# SA3_SS_SA_UL_0_SA_UL_PKA_EIP29T2_40920000h register map
Vendor: Texas Instruments
Peripheral module from a debugger description file (folder AM275x).
Registers are 32-bit, read-write, reset 0x0 unless marked. A register's access mark holds for its fields unless they carry their own. Offsets are as the file gives them; lines under a group give offsets from that group; [hi:lo] are bit positions; {n}, {i} and the like mark numbered series; 'fields as' and 'values as' point back to an identical list; <NAME> marks a mode.

## sa_ul_pka_eip29t2
0x00 SA_UL_PKA_EIP29T2_PKA_APTR — Please refer to eip29t2 HW Reference Manual for details
  [10:0] APTR
0x04 SA_UL_PKA_EIP29T2_PKA_BPTR — Please refer to eip29t2 HW Reference Manual for details
  [10:0] BPTR
0x08 SA_UL_PKA_EIP29T2_PKA_CPTR — Please refer to eip29t2 HW Reference Manual for details
  [10:0] CPTR
0x0C SA_UL_PKA_EIP29T2_PKA_DPTR — Please refer to eip29t2 HW Reference Manual for details
  [10:0] DPTR
0x10 SA_UL_PKA_EIP29T2_PKA_ALENGTH — Please refer to eip29t2 HW Reference Manual for details
  [8:0] ALENGTH
0x14 SA_UL_PKA_EIP29T2_PKA_BLENGTH — Please refer to eip29t2 HW Reference Manual for details
  [8:0] BLENGTH
0x18 SA_UL_PKA_EIP29T2_PKA_SHIFT — Please refer to eip29t2 HW Reference Manual for details
  [4:0] BITS_TO_SHIFT
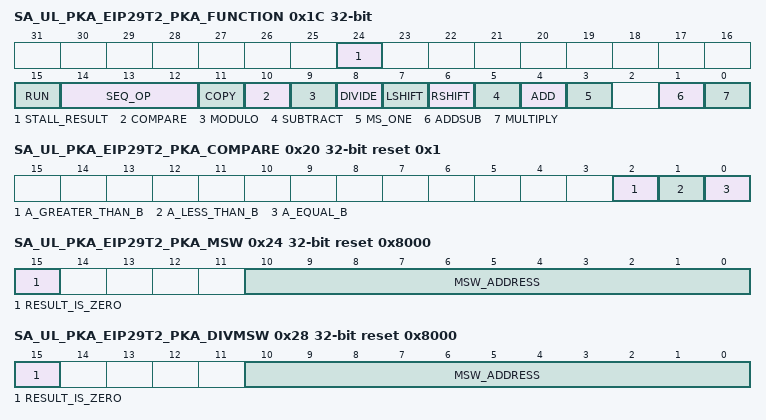
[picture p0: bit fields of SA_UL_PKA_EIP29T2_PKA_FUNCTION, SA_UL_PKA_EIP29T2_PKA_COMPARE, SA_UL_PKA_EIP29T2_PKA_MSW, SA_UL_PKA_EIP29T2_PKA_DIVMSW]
0x1C SA_UL_PKA_EIP29T2_PKA_FUNCTION access per field — Please refer to eip29t2 HW Reference Manual for details
  [24] STALL_RESULT rw — Please refer to eip29t2 HW Reference Manual for details
  [15] RUN wo — Please refer to eip29t2 HW Reference Manual for details
  [14:12] SEQ_OP rw — Please refer to eip29t2 HW Reference Manual for details
  [11] COPY rw — Please refer to eip29t2 HW Reference Manual for details
  [10] COMPARE rw — Please refer to eip29t2 HW Reference Manual for details
  [9] MODULO rw — Please refer to eip29t2 HW Reference Manual for details
  [8] DIVIDE rw — Please refer to eip29t2 HW Reference Manual for details
  [7] LSHIFT rw — Please refer to eip29t2 HW Reference Manual for details
  [6] RSHIFT rw — Please refer to eip29t2 HW Reference Manual for details
  [5] SUBTRACT rw — Please refer to eip29t2 HW Reference Manual for details
  [4] ADD rw — Please refer to eip29t2 HW Reference Manual for details
  [3] MS_ONE rw — Please refer to eip29t2 HW Reference Manual for details
  [1] ADDSUB rw — Please refer to eip29t2 HW Reference Manual for details
  [0] MULTIPLY rw — Please refer to eip29t2 HW Reference Manual for details
0x20 SA_UL_PKA_EIP29T2_PKA_COMPARE ro reset 0x1 — Please refer to eip29t2 HW Reference Manual for details
  [2] A_GREATER_THAN_B — Please refer to eip29t2 HW Reference Manual for details
  [1] A_LESS_THAN_B — Please refer to eip29t2 HW Reference Manual for details
  [0] A_EQUAL_B — Please refer to eip29t2 HW Reference Manual for details
0x24 SA_UL_PKA_EIP29T2_PKA_MSW ro reset 0x8000 — Please refer to eip29t2 HW Reference Manual for details
  [15] RESULT_IS_ZERO — Please refer to eip29t2 HW Reference Manual for details
  [10:0] MSW_ADDRESS — Please refer to eip29t2 HW Reference Manual for details
0x28 SA_UL_PKA_EIP29T2_PKA_DIVMSW ro reset 0x8000 — Please refer to eip29t2 HW Reference Manual for details
  fields as SA_UL_PKA_EIP29T2_PKA_MSW
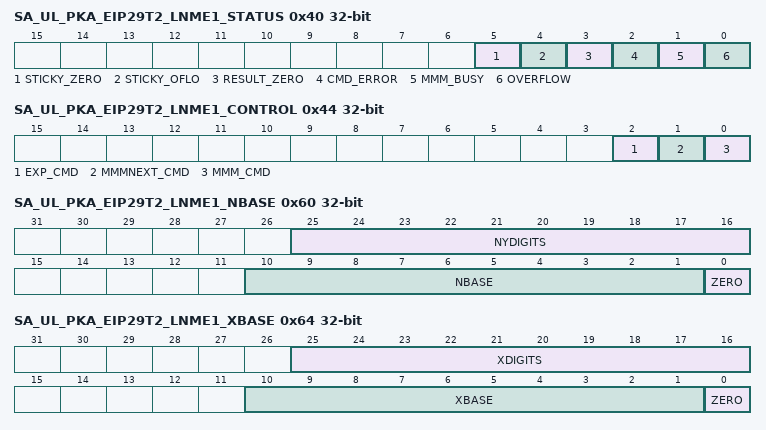
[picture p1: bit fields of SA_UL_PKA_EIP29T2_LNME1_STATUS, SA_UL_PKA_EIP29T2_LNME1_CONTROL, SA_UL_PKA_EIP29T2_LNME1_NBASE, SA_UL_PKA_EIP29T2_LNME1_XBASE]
0x40 SA_UL_PKA_EIP29T2_LNME1_STATUS — Please refer to eip29t2 HW Reference Manual for details
  [5] STICKY_ZERO — Please refer to eip29t2 HW Reference Manual for details
  [4] STICKY_OFLO — Please refer to eip29t2 HW Reference Manual for details
  [3] RESULT_ZERO — Please refer to eip29t2 HW Reference Manual for details
  [2] CMD_ERROR — Please refer to eip29t2 HW Reference Manual for details
  [1] MMM_BUSY — Please refer to eip29t2 HW Reference Manual for details
  [0] OVERFLOW — Please refer to eip29t2 HW Reference Manual for details
0x44 SA_UL_PKA_EIP29T2_LNME1_CONTROL — Please refer to eip29t2 HW Reference Manual for details
  [2] EXP_CMD — Please refer to eip29t2 HW Reference Manual for details
  [1] MMMNEXT_CMD — Please refer to eip29t2 HW Reference Manual for details
  [0] MMM_CMD — Please refer to eip29t2 HW Reference Manual for details
0x60 SA_UL_PKA_EIP29T2_LNME1_NBASE access per field — Please refer to eip29t2 HW Reference Manual for details
  [25:16] NYDIGITS rw — Please refer to eip29t2 HW Reference Manual for details
  [10:1] NBASE rw — Please refer to eip29t2 HW Reference Manual for details
  [0] ZERO ro — Please refer to eip29t2 HW Reference Manual for details
0x64 SA_UL_PKA_EIP29T2_LNME1_XBASE access per field — Please refer to eip29t2 HW Reference Manual for details
  [25:16] XDIGITS rw — Please refer to eip29t2 HW Reference Manual for details
  [10:1] XBASE rw — Please refer to eip29t2 HW Reference Manual for details
  [0] ZERO ro — Please refer to eip29t2 HW Reference Manual for details
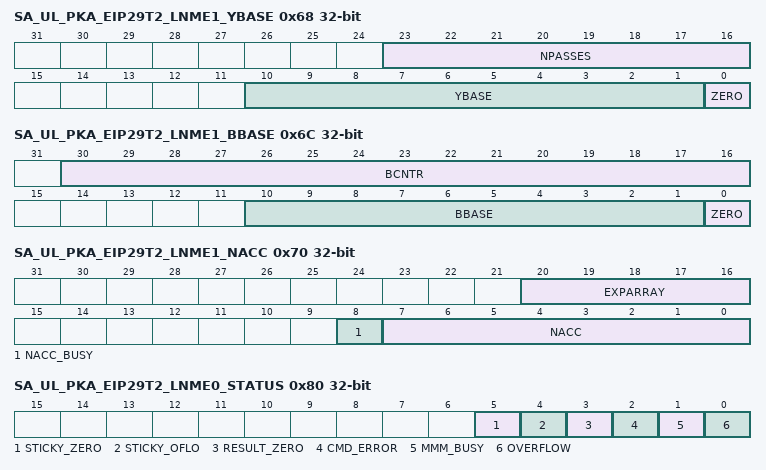
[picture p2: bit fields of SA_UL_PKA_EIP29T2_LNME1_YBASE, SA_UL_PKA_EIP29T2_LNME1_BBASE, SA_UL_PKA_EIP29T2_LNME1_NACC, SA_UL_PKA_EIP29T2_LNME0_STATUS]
0x68 SA_UL_PKA_EIP29T2_LNME1_YBASE access per field — Please refer to eip29t2 HW Reference Manual for details
  [23:16] NPASSES rw — Please refer to eip29t2 HW Reference Manual for details
  [10:1] YBASE rw — Please refer to eip29t2 HW Reference Manual for details
  [0] ZERO ro — Please refer to eip29t2 HW Reference Manual for details
0x6C SA_UL_PKA_EIP29T2_LNME1_BBASE access per field — Please refer to eip29t2 HW Reference Manual for details
  [30:16] BCNTR rw — Please refer to eip29t2 HW Reference Manual for details
  [10:1] BBASE rw — Please refer to eip29t2 HW Reference Manual for details
  [0] ZERO ro — Please refer to eip29t2 HW Reference Manual for details
0x70 SA_UL_PKA_EIP29T2_LNME1_NACC — Please refer to eip29t2 HW Reference Manual for details
  [20:16] EXPARRAY — Please refer to eip29t2 HW Reference Manual for details
  [8] NACC_BUSY — Please refer to eip29t2 HW Reference Manual for details
  [7:0] NACC — Please refer to eip29t2 HW Reference Manual for details
0x74 SA_UL_PKA_EIP29T2_LNME1_NZERO — Please refer to eip29t2 HW Reference Manual for details
  [7:0] NZERO
0x80 SA_UL_PKA_EIP29T2_LNME0_STATUS — Please refer to eip29t2 HW Reference Manual for details
  fields as SA_UL_PKA_EIP29T2_LNME1_STATUS
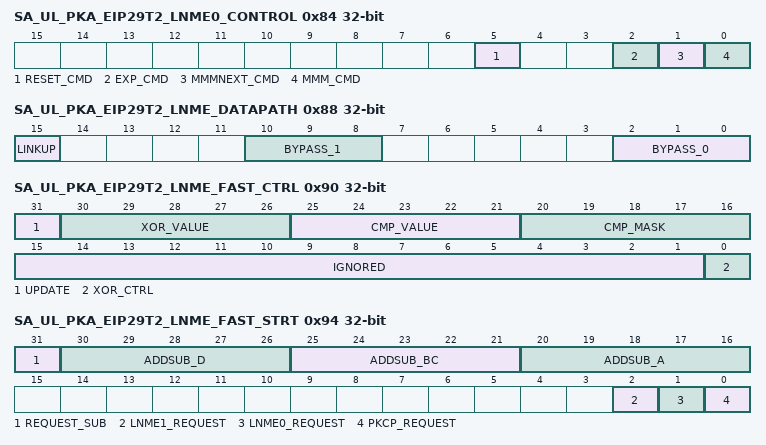
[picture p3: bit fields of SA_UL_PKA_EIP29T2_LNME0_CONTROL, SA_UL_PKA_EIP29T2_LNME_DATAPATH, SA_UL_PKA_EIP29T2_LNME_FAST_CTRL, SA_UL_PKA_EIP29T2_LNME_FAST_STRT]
0x84 SA_UL_PKA_EIP29T2_LNME0_CONTROL — Please refer to eip29t2 HW Reference Manual for details
  [5] RESET_CMD — Please refer to eip29t2 HW Reference Manual for details
  [2] EXP_CMD — Please refer to eip29t2 HW Reference Manual for details
  [1] MMMNEXT_CMD — Please refer to eip29t2 HW Reference Manual for details
  [0] MMM_CMD — Please refer to eip29t2 HW Reference Manual for details
0x88 SA_UL_PKA_EIP29T2_LNME_DATAPATH — Please refer to eip29t2 HW Reference Manual for details
  [15] LINKUP — Please refer to eip29t2 HW Reference Manual for details
  [10:8] BYPASS_1 — Please refer to eip29t2 HW Reference Manual for details
  [2:0] BYPASS_0 — Please refer to eip29t2 HW Reference Manual for details
0x90 SA_UL_PKA_EIP29T2_LNME_FAST_CTRL access per field — Please refer to eip29t2 HW Reference Manual for details
  [31] UPDATE wo — Please refer to eip29t2 HW Reference Manual for details
  [30:26] XOR_VALUE rw — Please refer to eip29t2 HW Reference Manual for details
  [25:21] CMP_VALUE rw — Please refer to eip29t2 HW Reference Manual for details
  [20:16] CMP_MASK rw — Please refer to eip29t2 HW Reference Manual for details
  [15:1] IGNORED ro — Please refer to eip29t2 HW Reference Manual for details
  [0] XOR_CTRL rw — Please refer to eip29t2 HW Reference Manual for details
0x94 SA_UL_PKA_EIP29T2_LNME_FAST_STRT — Please refer to eip29t2 HW Reference Manual for details
  [31] REQUEST_SUB — Please refer to eip29t2 HW Reference Manual for details
  [30:26] ADDSUB_D — Please refer to eip29t2 HW Reference Manual for details
  [25:21] ADDSUB_BC — Please refer to eip29t2 HW Reference Manual for details
  [20:16] ADDSUB_A — Please refer to eip29t2 HW Reference Manual for details
  [2] LNME1_REQUEST — Please refer to eip29t2 HW Reference Manual for details
  [1] LNME0_REQUEST — Please refer to eip29t2 HW Reference Manual for details
  [0] PKCP_REQUEST — Please refer to eip29t2 HW Reference Manual for details
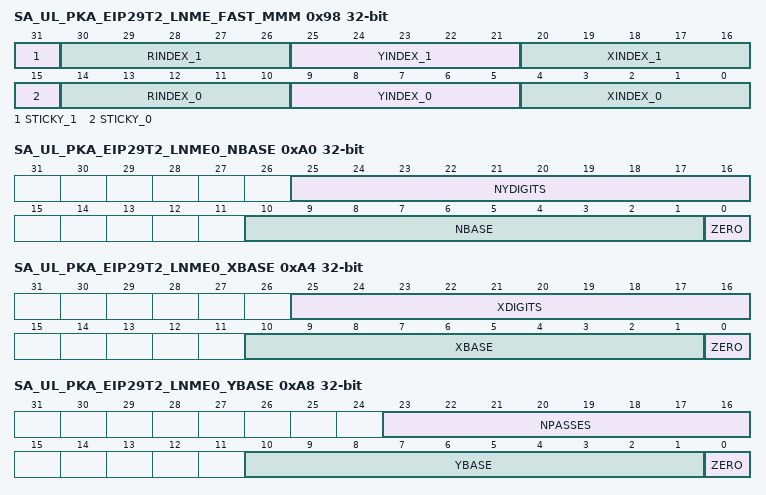
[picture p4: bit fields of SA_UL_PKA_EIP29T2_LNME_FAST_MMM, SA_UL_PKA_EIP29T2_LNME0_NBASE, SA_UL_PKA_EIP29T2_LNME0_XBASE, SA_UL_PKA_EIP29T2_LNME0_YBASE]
0x98 SA_UL_PKA_EIP29T2_LNME_FAST_MMM — Please refer to eip29t2 HW Reference Manual for details
  [31] STICKY_1 — Please refer to eip29t2 HW Reference Manual for details
  [30:26] RINDEX_1 — Please refer to eip29t2 HW Reference Manual for details
  [25:21] YINDEX_1 — Please refer to eip29t2 HW Reference Manual for details
  [20:16] XINDEX_1 — Please refer to eip29t2 HW Reference Manual for details
  [15] STICKY_0 — Please refer to eip29t2 HW Reference Manual for details
  [14:10] RINDEX_0 — Please refer to eip29t2 HW Reference Manual for details
  [9:5] YINDEX_0 — Please refer to eip29t2 HW Reference Manual for details
  [4:0] XINDEX_0 — Please refer to eip29t2 HW Reference Manual for details
0xA0 SA_UL_PKA_EIP29T2_LNME0_NBASE access per field — Please refer to eip29t2 HW Reference Manual for details
  fields as SA_UL_PKA_EIP29T2_LNME1_NBASE
0xA4 SA_UL_PKA_EIP29T2_LNME0_XBASE access per field — Please refer to eip29t2 HW Reference Manual for details
  fields as SA_UL_PKA_EIP29T2_LNME1_XBASE
0xA8 SA_UL_PKA_EIP29T2_LNME0_YBASE access per field — Please refer to eip29t2 HW Reference Manual for details
  fields as SA_UL_PKA_EIP29T2_LNME1_YBASE
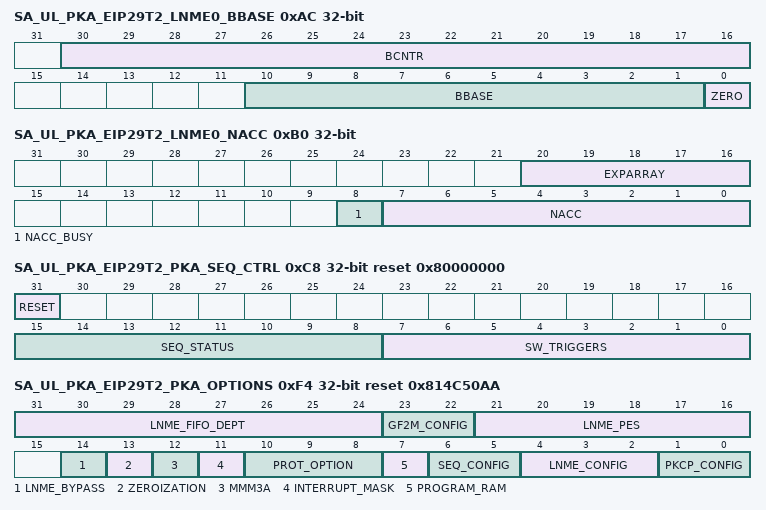
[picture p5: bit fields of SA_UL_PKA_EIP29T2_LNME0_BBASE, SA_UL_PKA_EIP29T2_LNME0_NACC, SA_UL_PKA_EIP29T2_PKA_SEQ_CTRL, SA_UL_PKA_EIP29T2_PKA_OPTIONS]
0xAC SA_UL_PKA_EIP29T2_LNME0_BBASE access per field — Please refer to eip29t2 HW Reference Manual for details
  fields as SA_UL_PKA_EIP29T2_LNME1_BBASE
0xB0 SA_UL_PKA_EIP29T2_LNME0_NACC — Please refer to eip29t2 HW Reference Manual for details
  fields as SA_UL_PKA_EIP29T2_LNME1_NACC
0xB4 SA_UL_PKA_EIP29T2_LNME0_NZERO — Please refer to eip29t2 HW Reference Manual for details
  [7:0] NZERO
0xC8 SA_UL_PKA_EIP29T2_PKA_SEQ_CTRL access per field reset 0x80000000 — Please refer to eip29t2 HW Reference Manual for details
  [31] RESET rw — Please refer to eip29t2 HW Reference Manual for details
  [15:8] SEQ_STATUS ro — Please refer to eip29t2 HW Reference Manual for details
  [7:0] SW_TRIGGERS rw — Please refer to eip29t2 HW Reference Manual for details
0xF4 SA_UL_PKA_EIP29T2_PKA_OPTIONS ro reset 0x814C50AA — Please refer to eip29t2 HW Reference Manual for details
  [31:24] LNME_FIFO_DEPT — Please refer to eip29t2 HW Reference Manual for details
  [23:22] GF2M_CONFIG — Please refer to eip29t2 HW Reference Manual for details
  [21:16] LNME_PES — Please refer to eip29t2 HW Reference Manual for details
  [14] LNME_BYPASS — Please refer to eip29t2 HW Reference Manual for details
  [13] ZEROIZATION — Please refer to eip29t2 HW Reference Manual for details
  [12] MMM3A — Please refer to eip29t2 HW Reference Manual for details
  [11] INTERRUPT_MASK — Please refer to eip29t2 HW Reference Manual for details
  [10:8] PROT_OPTION — Please refer to eip29t2 HW Reference Manual for details
  [7] PROGRAM_RAM — Please refer to eip29t2 HW Reference Manual for details
  [6:5] SEQ_CONFIG — Please refer to eip29t2 HW Reference Manual for details
  [4:2] LNME_CONFIG — Please refer to eip29t2 HW Reference Manual for details
  [1:0] PKCP_CONFIG — Please refer to eip29t2 HW Reference Manual for details
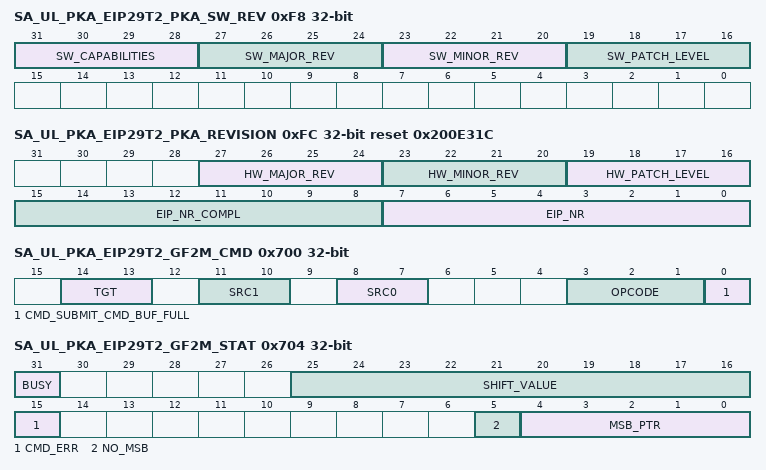
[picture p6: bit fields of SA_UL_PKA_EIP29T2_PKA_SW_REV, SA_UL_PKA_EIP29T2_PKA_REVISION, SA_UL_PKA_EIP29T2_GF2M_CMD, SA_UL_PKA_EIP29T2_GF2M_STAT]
0xF8 SA_UL_PKA_EIP29T2_PKA_SW_REV ro — Please refer to eip29t2 HW Reference Manual for details
  [31:28] SW_CAPABILITIES — Please refer to eip29t2 HW Reference Manual for details
  [27:24] SW_MAJOR_REV — Please refer to eip29t2 HW Reference Manual for details
  [23:20] SW_MINOR_REV — Please refer to eip29t2 HW Reference Manual for details
  [19:16] SW_PATCH_LEVEL — Please refer to eip29t2 HW Reference Manual for details
0xFC SA_UL_PKA_EIP29T2_PKA_REVISION ro reset 0x200E31C — Please refer to eip29t2 HW Reference Manual for details
  [27:24] HW_MAJOR_REV — Please refer to eip29t2 HW Reference Manual for details
  [23:20] HW_MINOR_REV — Please refer to eip29t2 HW Reference Manual for details
  [19:16] HW_PATCH_LEVEL — Please refer to eip29t2 HW Reference Manual for details
  [15:8] EIP_NR_COMPL — Please refer to eip29t2 HW Reference Manual for details
  [7:0] EIP_NR — Please refer to eip29t2 HW Reference Manual for details
{0x400+4i} SA_UL_PKA_EIP29T2_GF2M_OPERAND_A_{i} (i=0..16) — Please refer to eip29t2 HW Reference Manual for details
  [31:0] GF2M_OPERAND_A_{i}
0x444 SA_UL_PKA_EIP29T2_GF2M_OPERAND_A_17 — Please refer to eip29t2 HW Reference Manual for details
  [27:0] OPERAND_A
{0x480+4i} SA_UL_PKA_EIP29T2_GF2M_OPERAND_B_{i} (i=0..16) — Please refer to eip29t2 HW Reference Manual for details
  [31:0] GF2M_OPERAND_B_{i}
0x4C4 SA_UL_PKA_EIP29T2_GF2M_OPERAND_B_17 — Please refer to eip29t2 HW Reference Manual for details
  [27:0] OPERAND_B
{0x500+4i} SA_UL_PKA_EIP29T2_GF2M_OPERAND_C_{i} (i=0..16) — Please refer to eip29t2 HW Reference Manual for details
  [31:0] GF2M_OPERAND_C_{i}
0x544 SA_UL_PKA_EIP29T2_GF2M_OPERAND_C_17 — Please refer to eip29t2 HW Reference Manual for details
  [27:0] OPERAND_C
{0x580+4i} SA_UL_PKA_EIP29T2_GF2M_OPERAND_D_{i} (i=0..16) — Please refer to eip29t2 HW Reference Manual for details
  [31:0] GF2M_OPERAND_D_{i}
0x5C4 SA_UL_PKA_EIP29T2_GF2M_OPERAND_D_17 — Please refer to eip29t2 HW Reference Manual for details
  [27:0] OPERAND_D
{0x600+4i} SA_UL_PKA_EIP29T2_GF2M_POLYNOMIAL_{i} (i=0..16) — Please refer to eip29t2 HW Reference Manual for details
  [31:0] GF2M_POLYNOMIAL_{i}
0x644 SA_UL_PKA_EIP29T2_GF2M_POLYNOMIAL_17 — Please refer to eip29t2 HW Reference Manual for details
  [27:0] POLYNOMIAL
0x700 SA_UL_PKA_EIP29T2_GF2M_CMD access per field — Please refer to eip29t2 HW Reference Manual for details
  [14:13] TGT rw — Please refer to eip29t2 HW Reference Manual for details
  [11:10] SRC1 rw — Please refer to eip29t2 HW Reference Manual for details
  [8:7] SRC0 rw — Please refer to eip29t2 HW Reference Manual for details
  [3:1] OPCODE rw — Please refer to eip29t2 HW Reference Manual for details
  [0] CMD_SUBMIT_CMD_BUF_FULL wo — Please refer to eip29t2 HW Reference Manual for details
0x704 SA_UL_PKA_EIP29T2_GF2M_STAT ro — Please refer to eip29t2 HW Reference Manual for details
  [31] BUSY — Please refer to eip29t2 HW Reference Manual for details
  [25:16] SHIFT_VALUE — Please refer to eip29t2 HW Reference Manual for details
  [15] CMD_ERR — Please refer to eip29t2 HW Reference Manual for details
  [5] NO_MSB — Please refer to eip29t2 HW Reference Manual for details
  [4:0] MSB_PTR — Please refer to eip29t2 HW Reference Manual for details
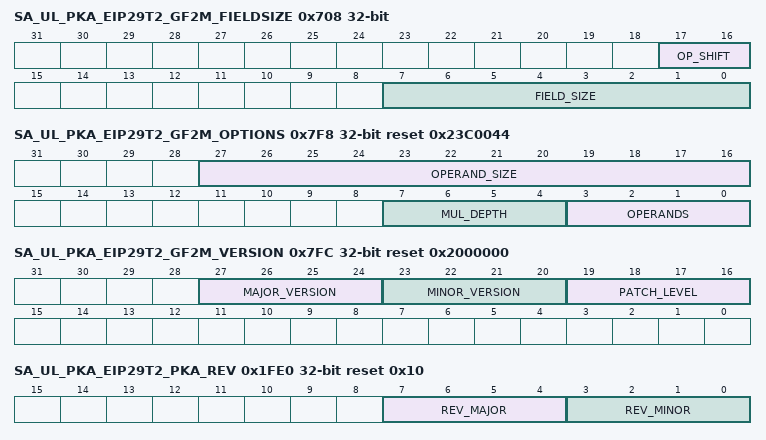
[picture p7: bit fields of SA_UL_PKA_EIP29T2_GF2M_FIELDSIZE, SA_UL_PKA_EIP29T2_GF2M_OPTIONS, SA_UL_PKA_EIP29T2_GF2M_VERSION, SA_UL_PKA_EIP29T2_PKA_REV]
0x708 SA_UL_PKA_EIP29T2_GF2M_FIELDSIZE — Please refer to eip29t2 HW Reference Manual for details
  [17:16] OP_SHIFT — Please refer to eip29t2 HW Reference Manual for details
  [7:0] FIELD_SIZE — Please refer to eip29t2 HW Reference Manual for details
0x7F8 SA_UL_PKA_EIP29T2_GF2M_OPTIONS ro reset 0x23C0044 — Please refer to eip29t2 HW Reference Manual for details
  [27:16] OPERAND_SIZE — Please refer to eip29t2 HW Reference Manual for details
  [7:4] MUL_DEPTH — Please refer to eip29t2 HW Reference Manual for details
  [3:0] OPERANDS — Please refer to eip29t2 HW Reference Manual for details
0x7FC SA_UL_PKA_EIP29T2_GF2M_VERSION ro reset 0x2000000 — Please refer to eip29t2 HW Reference Manual for details
  [27:24] MAJOR_VERSION — Please refer to eip29t2 HW Reference Manual for details
  [23:20] MINOR_VERSION — Please refer to eip29t2 HW Reference Manual for details
  [19:16] PATCH_LEVEL — Please refer to eip29t2 HW Reference Manual for details
0x1FE0 SA_UL_PKA_EIP29T2_PKA_REV ro reset 0x10 — Please refer to eip29t2 HW Reference Manual for details
  [7:4] REV_MAJOR — Please refer to eip29t2 HW Reference Manual for details
  [3:0] REV_MINOR — Please refer to eip29t2 HW Reference Manual for details
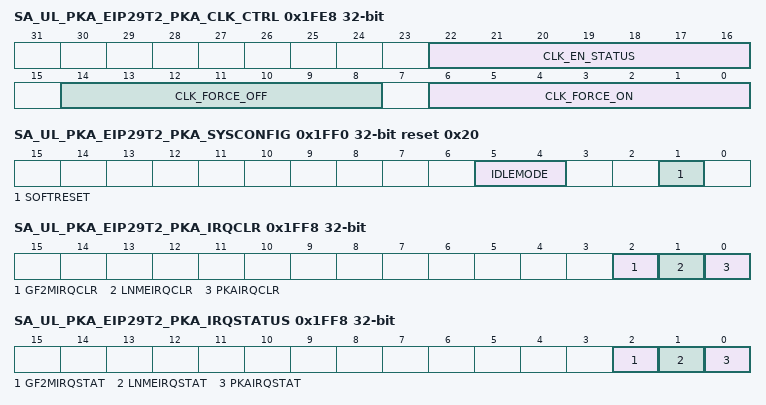
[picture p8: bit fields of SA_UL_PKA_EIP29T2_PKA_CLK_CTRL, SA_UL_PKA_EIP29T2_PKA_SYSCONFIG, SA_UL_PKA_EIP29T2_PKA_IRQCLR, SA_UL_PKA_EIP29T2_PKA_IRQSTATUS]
0x1FE8 SA_UL_PKA_EIP29T2_PKA_CLK_CTRL access per field — Please refer to eip29t2 HW Reference Manual for details
  [22:16] CLK_EN_STATUS ro — Please refer to eip29t2 HW Reference Manual for details
  [14:8] CLK_FORCE_OFF rw — Please refer to eip29t2 HW Reference Manual for details
  [6:0] CLK_FORCE_ON rw — Please refer to eip29t2 HW Reference Manual for details
0x1FF0 SA_UL_PKA_EIP29T2_PKA_SYSCONFIG reset 0x20 — Please refer to eip29t2 HW Reference Manual for details
  [5:4] IDLEMODE — Please refer to eip29t2 HW Reference Manual for details
  [1] SOFTRESET — Please refer to eip29t2 HW Reference Manual for details
0x1FF4 SA_UL_PKA_EIP29T2_PKA_SYSSTATUS ro reset 0x1 — Please refer to eip29t2 HW Reference Manual for details
  [0] RESETDONE
0x1FF8 SA_UL_PKA_EIP29T2_PKA_IRQCLR wo — Please refer to eip29t2 HW Reference Manual for details
  [2] GF2MIRQCLR — Please refer to eip29t2 HW Reference Manual for details
  [1] LNMEIRQCLR — Please refer to eip29t2 HW Reference Manual for details
  [0] PKAIRQCLR — Please refer to eip29t2 HW Reference Manual for details
0x1FF8 SA_UL_PKA_EIP29T2_PKA_IRQSTATUS ro — Please refer to eip29t2 HW Reference Manual for details
  [2] GF2MIRQSTAT — Please refer to eip29t2 HW Reference Manual for details
  [1] LNMEIRQSTAT — Please refer to eip29t2 HW Reference Manual for details
  [0] PKAIRQSTAT — Please refer to eip29t2 HW Reference Manual for details
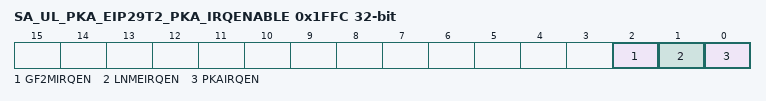
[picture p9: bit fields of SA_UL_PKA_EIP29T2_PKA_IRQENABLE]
0x1FFC SA_UL_PKA_EIP29T2_PKA_IRQENABLE — Please refer to eip29t2 HW Reference Manual for details
  [2] GF2MIRQEN — Please refer to eip29t2 HW Reference Manual for details
  [1] LNMEIRQEN — Please refer to eip29t2 HW Reference Manual for details
  [0] PKAIRQEN — Please refer to eip29t2 HW Reference Manual for details
